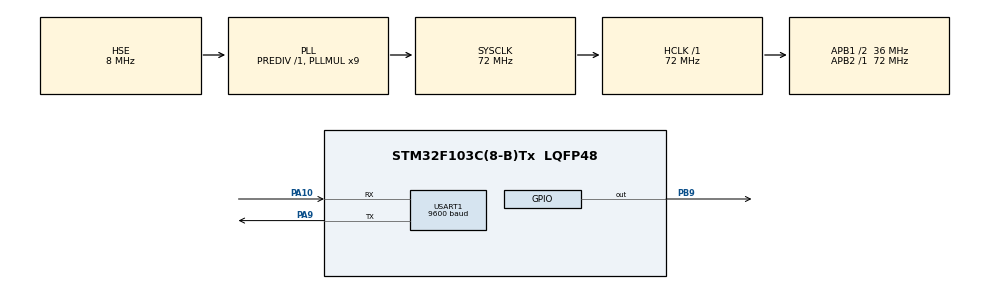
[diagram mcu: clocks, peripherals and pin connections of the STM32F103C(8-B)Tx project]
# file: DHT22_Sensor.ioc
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Mcu.Family=STM32F1
Mcu.Name=STM32F103C(8-B)Tx
Mcu.Package=LQFP48
NVIC.PriorityGroup=NVIC_PRIORITYGROUP_4
PA10.Mode=Asynchronous
PA10.Signal=USART1_RX
PA13.Mode=Serial_Wire
PA13.Signal=SYS_JTMS-SWDIO
PA14.Mode=Serial_Wire
PA14.Signal=SYS_JTCK-SWCLK
PA9.Mode=Asynchronous
PA9.Signal=USART1_TX
PB9.Signal=GPIO_Output
PD0-OSC_IN.Mode=HSE-External-Oscillator
PD0-OSC_IN.Signal=RCC_OSC_IN
PD1-OSC_OUT.Mode=HSE-External-Oscillator
PD1-OSC_OUT.Signal=RCC_OSC_OUT
ProjectManager.HeapSize=0x200
ProjectManager.StackSize=0x400
ProjectManager.TargetToolchain=STM32CubeIDE
RCC.AHBFreq_Value=72000000
RCC.APB1CLKDivider=RCC_HCLK_DIV2
RCC.APB1Freq_Value=36000000
RCC.APB1TimFreq_Value=72000000
RCC.APB2Freq_Value=72000000
RCC.APB2TimFreq_Value=72000000
RCC.HCLKFreq_Value=72000000
RCC.PLLMUL=RCC_PLL_MUL9
RCC.PLLSourceVirtual=RCC_PLLSOURCE_HSE
RCC.SYSCLKFreq_VALUE=72000000
RCC.SYSCLKSource=RCC_SYSCLKSOURCE_PLLCLK
RCC.USBFreq_Value=72000000
TIM1.Prescaler=71
USART1.BaudRate=9600
USART1.VirtualMode=VM_ASYNC
VP_TIM1_VS_ClockSourceINT.Mode=Internal
board=custom

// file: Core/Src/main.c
/* USER CODE BEGIN Header */
/**
  ******************************************************************************
  * @file           : main.c
  * @brief          : Main program body
  ******************************************************************************
  * @attention
  *
  * Copyright (c) 2024 STMicroelectronics.
  * All rights reserved.
  *
  * This software is licensed under terms that can be found in the LICENSE file
  * in the root directory of this software component.
  * If no LICENSE file comes with this software, it is provided AS-IS.
  *
  ******************************************************************************
  */
/* USER CODE END Header */
#include "main.h"

/* USER CODE BEGIN Includes */
#include "uart.h"
#include "stdio.h"
#include "string.h"
//#include "DHT22_LIB.h"
/* USER CODE END Includes */

/* USER CODE BEGIN PTD */
/*
	typedef struct {
			float temperature;
			float humidity;
	} SensorData;

	SensorData DHT22;
*/
/* USER CODE END PTD */

/* USER CODE BEGIN PD */
#define DHT22_Pin GPIO_PIN_9
#define DHT22_GPIO_Port GPIOB
/* USER CODE END PD */

TIM_HandleTypeDef htim1;

UART_HandleTypeDef huart1;

char outputBuffer[50];

/* USER CODE BEGIN PV */

char message1[16];
char message2[16];
uint8_t TOUT = 0, CheckSum, i;
uint8_t T_Byte1, T_Byte2, RH_Byte1, RH_Byte2;
float Voltage_mV = 0;
float Temperature_C = 0;
float Temperature_F = 0;
char msg[50];

float temperature = 0.0f;
float humidity = 0.0f;
/* USER CODE END PV */

void SystemClock_Config(void);
static void MX_GPIO_Init(void);
static void MX_TIM1_Init(void);
static void MX_USART1_UART_Init(void);

/* USER CODE BEGIN 0 */

/*********************************** DHT22 Function ***************************/

void delay_us(uint16_t us)
{

	__HAL_TIM_SET_COUNTER(&htim1,0);
	while(__HAL_TIM_GET_COUNTER(&htim1) < us);
}

void start_signal(void) {
    GPIO_InitTypeDef GPIO_InitStruct = {0};
    GPIO_InitStruct.Pin = DHT22_Pin;
    GPIO_InitStruct.Mode = GPIO_MODE_OUTPUT_PP;
    GPIO_InitStruct.Pull = GPIO_NOPULL;
    GPIO_InitStruct.Speed = GPIO_SPEED_FREQ_LOW;
    HAL_GPIO_Init(DHT22_GPIO_Port, &GPIO_InitStruct);

    HAL_GPIO_WritePin(DHT22_GPIO_Port, DHT22_Pin, GPIO_PIN_RESET);
    HAL_Delay(18);
    HAL_GPIO_WritePin(DHT22_GPIO_Port, DHT22_Pin, GPIO_PIN_SET);
    delay_us(30); // Wait 20-40μs

    GPIO_InitStruct.Mode = GPIO_MODE_INPUT;
    HAL_GPIO_Init(DHT22_GPIO_Port, &GPIO_InitStruct);
}

uint8_t check_response(void) {
    TOUT = 0;
    __HAL_TIM_SET_COUNTER(&htim1, 0);
    while (!HAL_GPIO_ReadPin(DHT22_GPIO_Port, DHT22_Pin) && (__HAL_TIM_GET_COUNTER(&htim1) < 100)) {};
    if (__HAL_TIM_GET_COUNTER(&htim1) >= 100)
        return 0;

    __HAL_TIM_SET_COUNTER(&htim1, 0);
    while (HAL_GPIO_ReadPin(DHT22_GPIO_Port, DHT22_Pin) && (__HAL_TIM_GET_COUNTER(&htim1) < 100)) {};
    if (__HAL_TIM_GET_COUNTER(&htim1) >= 100)
        return 0;

    return 1;
}

uint8_t read_byte(void) {
    uint8_t num = 0;
    for (i = 0; i < 8; i++) {
        while (!HAL_GPIO_ReadPin(DHT22_GPIO_Port, DHT22_Pin)) {};
        __HAL_TIM_SET_COUNTER(&htim1, 0);
        while (HAL_GPIO_ReadPin(DHT22_GPIO_Port, DHT22_Pin)) {};
        if (__HAL_TIM_GET_COUNTER(&htim1) > 40) // 40μs threshold
            num |= (1 << (7 - i));
    }
    return num;
}

void send_uart(char *string) {
    HAL_UART_Transmit(&huart1, (uint8_t*)string, strlen(string), HAL_MAX_DELAY);
}

/************************************ DHT22 ******************************************/

/* USER CODE END 0 */

int main(void)
{

  /* MCU Configuration--------------------------------------------------------*/

  /* Reset of all peripherals, Initializes the Flash interface and the Systick. */
  HAL_Init();

  /* Configure the system clock */
  SystemClock_Config();

  /* Initialize all configured peripherals */
  MX_GPIO_Init();
  MX_TIM1_Init();
  MX_USART1_UART_Init();
  /* USER CODE BEGIN 2 */
  /* USER CODE BEGIN 2 */
 HAL_TIM_Base_Start(&htim1);
 send_uart("Initialization complete\n\r");
     /* USER CODE END 2 */

  while (1)
  {
    /* USER CODE END WHILE */

	  HAL_Delay(1000); // Delay for 1 second
	          start_signal(); // Send start signal to DHT22

	          uint8_t check = check_response();
	          if (!check) {
	              send_uart("No response from the sensor\r\n");
	          } else {
	              // Read bytes from DHT22
	              RH_Byte1 = read_byte();
	              RH_Byte2 = read_byte();
	              T_Byte1 = read_byte();
	              T_Byte2 = read_byte();
	              CheckSum = read_byte();

	              // Combine humidity and temperature bytes
	              uint16_t rh = (RH_Byte1 << 8) | RH_Byte2;
	              uint16_t temp = (T_Byte1 << 8) | T_Byte2;
	              uint8_t sign = 0;

	              // Check if temperature is negative
	              if (temp > 0x8000) {
	                  temp &= 0x7FFF; // Clear the sign bit
	                  sign = 1; // Indicate negative temperature
	              }

	              char rh_buf[8], temp_buf[8];
	              sprintf(rh_buf, "%2.2u", rh);
	              sprintf(temp_buf, "%2.2u", temp);

	              // Check checksum
	              if (CheckSum == ((RH_Byte1 + RH_Byte2 + T_Byte1 + T_Byte2) & 0xFF)) {
	                  sprintf(msg, "RH = %3u.%1u %% ", rh / 10, rh % 10);
	                  send_uart(msg);
	                  sprintf(msg, "Temp = %c%3u.%1u C \r\n", sign ? '-' : ' ', temp / 10, temp % 10);
	                  send_uart(msg);
	              } else {
	                  send_uart("Checksum Error! Trying Again ...\r\n");
	              }
	          }
	      }
  }

void SystemClock_Config(void)
{
  RCC_OscInitTypeDef RCC_OscInitStruct = {0};
  RCC_ClkInitTypeDef RCC_ClkInitStruct = {0};

  /** Initializes the RCC Oscillators according to the specified parameters
  * in the RCC_OscInitTypeDef structure.
  */
  RCC_OscInitStruct.OscillatorType = RCC_OSCILLATORTYPE_HSE;
  RCC_OscInitStruct.HSEState = RCC_HSE_ON;
  RCC_OscInitStruct.HSEPredivValue = RCC_HSE_PREDIV_DIV1;
  RCC_OscInitStruct.HSIState = RCC_HSI_ON;
  RCC_OscInitStruct.PLL.PLLState = RCC_PLL_ON;
  RCC_OscInitStruct.PLL.PLLSource = RCC_PLLSOURCE_HSE;
  RCC_OscInitStruct.PLL.PLLMUL = RCC_PLL_MUL9;
  if (HAL_RCC_OscConfig(&RCC_OscInitStruct) != HAL_OK)
  {
    Error_Handler();
  }

  /** Initializes the CPU, AHB and APB buses clocks
  */
  RCC_ClkInitStruct.ClockType = RCC_CLOCKTYPE_HCLK|RCC_CLOCKTYPE_SYSCLK
                              |RCC_CLOCKTYPE_PCLK1|RCC_CLOCKTYPE_PCLK2;
  RCC_ClkInitStruct.SYSCLKSource = RCC_SYSCLKSOURCE_PLLCLK;
  RCC_ClkInitStruct.AHBCLKDivider = RCC_SYSCLK_DIV1;
  RCC_ClkInitStruct.APB1CLKDivider = RCC_HCLK_DIV2;
  RCC_ClkInitStruct.APB2CLKDivider = RCC_HCLK_DIV1;

  if (HAL_RCC_ClockConfig(&RCC_ClkInitStruct, FLASH_LATENCY_2) != HAL_OK)
  {
    Error_Handler();
  }
}

static void MX_TIM1_Init(void)
{

  TIM_ClockConfigTypeDef sClockSourceConfig = {0};
  TIM_MasterConfigTypeDef sMasterConfig = {0};

  htim1.Instance = TIM1;
  htim1.Init.Prescaler = 71;
  htim1.Init.CounterMode = TIM_COUNTERMODE_UP;
  htim1.Init.Period = 65535;
  htim1.Init.ClockDivision = TIM_CLOCKDIVISION_DIV1;
  htim1.Init.RepetitionCounter = 0;
  htim1.Init.AutoReloadPreload = TIM_AUTORELOAD_PRELOAD_DISABLE;
  if (HAL_TIM_Base_Init(&htim1) != HAL_OK)
  {
    Error_Handler();
  }
  sClockSourceConfig.ClockSource = TIM_CLOCKSOURCE_INTERNAL;
  if (HAL_TIM_ConfigClockSource(&htim1, &sClockSourceConfig) != HAL_OK)
  {
    Error_Handler();
  }
  sMasterConfig.MasterOutputTrigger = TIM_TRGO_RESET;
  sMasterConfig.MasterSlaveMode = TIM_MASTERSLAVEMODE_DISABLE;
  if (HAL_TIMEx_MasterConfigSynchronization(&htim1, &sMasterConfig) != HAL_OK)
  {
    Error_Handler();
  }

}

static void MX_USART1_UART_Init(void)
{

  huart1.Instance = USART1;
  huart1.Init.BaudRate = 9600;
  huart1.Init.WordLength = UART_WORDLENGTH_8B;
  huart1.Init.StopBits = UART_STOPBITS_1;
  huart1.Init.Parity = UART_PARITY_NONE;
  huart1.Init.Mode = UART_MODE_TX_RX;
  huart1.Init.HwFlowCtl = UART_HWCONTROL_NONE;
  huart1.Init.OverSampling = UART_OVERSAMPLING_16;
  if (HAL_UART_Init(&huart1) != HAL_OK)
  {
    Error_Handler();
  }

}

static void MX_GPIO_Init(void)
{
  GPIO_InitTypeDef GPIO_InitStruct = {0};

  /* GPIO Ports Clock Enable */
  __HAL_RCC_GPIOD_CLK_ENABLE();
  __HAL_RCC_GPIOA_CLK_ENABLE();
  __HAL_RCC_GPIOB_CLK_ENABLE();

  /*Configure GPIO pin Output Level */
  HAL_GPIO_WritePin(GPIOB, GPIO_PIN_9, GPIO_PIN_RESET);

  /*Configure GPIO pin : PB9 */
  GPIO_InitStruct.Pin = GPIO_PIN_9;
  GPIO_InitStruct.Mode = GPIO_MODE_OUTPUT_PP;
  GPIO_InitStruct.Pull = GPIO_NOPULL;
  GPIO_InitStruct.Speed = GPIO_SPEED_FREQ_LOW;
  HAL_GPIO_Init(GPIOB, &GPIO_InitStruct);

}

void Error_Handler(void)
{
  __disable_irq();
  while (1)
  {
  }
}
